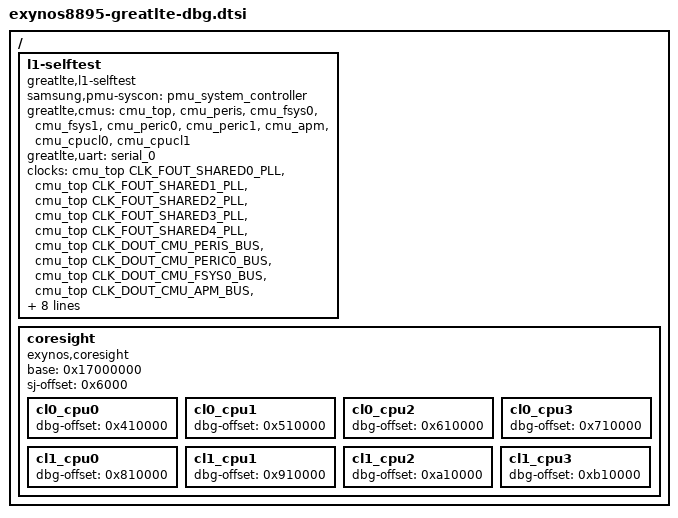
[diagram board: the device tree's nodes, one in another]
// SPDX-License-Identifier: GPL-2.0 OR BSD-3-Clause
/*
 * Samsung Galaxy Note 8 (greatlte, SM-N950N) board DT, part "dbg":
 * DEBUG only: bring-up self-test nodes (plan 2.2 row 16).
 *
 * Included at the end of exynos8895-greatlte.dts, after L0's nodes, in the merge
 * order of FULL_IMAGE_PLAN.md 2.2. Owner: WP-DBG; no other work package edits this
 * file (plan 2.3 rule D1). A node that two parts both configure (&usi9, &usi10)
 * is written identically in both files: dtc lets the later file win on a differing
 * value, which gl-verify V-DUP reports as an error. L0's reserved-memory stays in
 * the .dts; carveout additions and flag changes are &label edits here (plan X-8).
 */

/ {
	/*
	 * L1 self-test (spec/L1_platform.md 4.7, 5.9; drivers/soc/samsung/greatlte-l1-selftest.c,
	 * CONFIG_GREATLTE_L1_SELFTEST). Port-local debug binding, never upstream. The driver
	 * only reads: clk_get()/clk_get_rate()/__clk_is_enabled() of the clocks below, the PMU
	 * through the syscon, and of_iomap() reads of the listed CMUs.
	 */
	l1-selftest {
		compatible = "greatlte,l1-selftest";
		samsung,pmu-syscon = <&pmu_system_controller>;
		greatlte,cmus = <&cmu_top>, <&cmu_peris>, <&cmu_fsys0>, <&cmu_fsys1>,
				<&cmu_peric0>, <&cmu_peric1>, <&cmu_apm>, <&cmu_cpucl0>,
				<&cmu_cpucl1>;
		greatlte,uart = <&serial_0>;
		clocks = <&cmu_top CLK_FOUT_SHARED0_PLL>, <&cmu_top CLK_FOUT_SHARED1_PLL>,
			 <&cmu_top CLK_FOUT_SHARED2_PLL>, <&cmu_top CLK_FOUT_SHARED3_PLL>,
			 <&cmu_top CLK_FOUT_SHARED4_PLL>, <&cmu_top CLK_DOUT_CMU_PERIS_BUS>,
			 <&cmu_top CLK_DOUT_CMU_PERIC0_BUS>, <&cmu_top CLK_DOUT_CMU_FSYS0_BUS>,
			 <&cmu_top CLK_DOUT_CMU_APM_BUS>, <&cmu_peris CLK_GOUT_PERIS_GIC_CLK>,
			 <&cmu_apm CLK_GOUT_APM_MAILBOX_APM2AP_PCLK>,
			 <&cmu_cpucl0 CLK_FOUT_CPUCL0_PLL>, <&cmu_cpucl0 CLK_MOUT_PLL_CPUCL0>,
			 <&cmu_cpucl0 CLK_DOUT_CPUCL0_CPU>,
			 <&cmu_cpucl1 CLK_FOUT_CPUCL1_PLL>, <&cmu_cpucl1 CLK_MOUT_PLL_CPUCL1>,
			 <&cmu_cpucl1 CLK_DOUT_CPUCL1_CPU>;
		clock-names = "shared0", "shared1", "shared2", "shared3", "shared4",
			      "peris_bus", "peric0_bus", "fsys0_bus", "apm_bus", "gic",
			      "apm_mbox", "cpucl0_pll", "cpucl0_byp", "cpucl0",
			      "cpucl1_pll", "cpucl1_byp", "cpucl1";
	};

	/*
	 * DEBUG: CoreSight debug blocks, read only at panic for the PC of a CPU that hangs with
	 * its interrupts masked (drivers/soc/samsung/greatlte-cspc.c, CONFIG_GREATLTE_CSPC).
	 * Stock node FDT:7758-7819 without the ETM/funnel/ETF parts; children in stock order,
	 * cl<MPIDR aff1>_cpu<aff0>, and without unit addresses (they have no reg).
	 */
	coresight {
		compatible = "exynos,coresight";
		base = <0x17000000>;		/* FDT:7760 */
		sj-offset = <0x6000>;		/* FDT:7761 */

		cl0_cpu0 { device_type = "cs"; dbg-offset = <0x410000>; };	/* FDT:7765-7770 */
		cl0_cpu1 { device_type = "cs"; dbg-offset = <0x510000>; };	/* FDT:7772-7777 */
		cl0_cpu2 { device_type = "cs"; dbg-offset = <0x610000>; };	/* FDT:7779-7784 */
		cl0_cpu3 { device_type = "cs"; dbg-offset = <0x710000>; };	/* FDT:7786-7791 */
		cl1_cpu0 { device_type = "cs"; dbg-offset = <0x810000>; };	/* FDT:7793-7798 */
		cl1_cpu1 { device_type = "cs"; dbg-offset = <0x910000>; };	/* FDT:7800-7805 */
		cl1_cpu2 { device_type = "cs"; dbg-offset = <0xa10000>; };	/* FDT:7807-7812 */
		cl1_cpu3 { device_type = "cs"; dbg-offset = <0xb10000>; };	/* FDT:7814-7819 */
	};
};
